# PRU_ICSS_MDIO register map
Vendor: Texas Instruments
Peripheral module from a debugger description file (folder am437x).
Registers are 32-bit, access per field, no defined reset value unless marked. A register's access mark holds for its fields unless they carry their own. Offsets are as the file gives them; lines under a group give offsets from that group; [hi:lo] are bit positions; {n}, {i} and the like mark numbered series; 'fields as' and 'values as' point back to an identical list; <NAME> marks a mode.

## MDIO
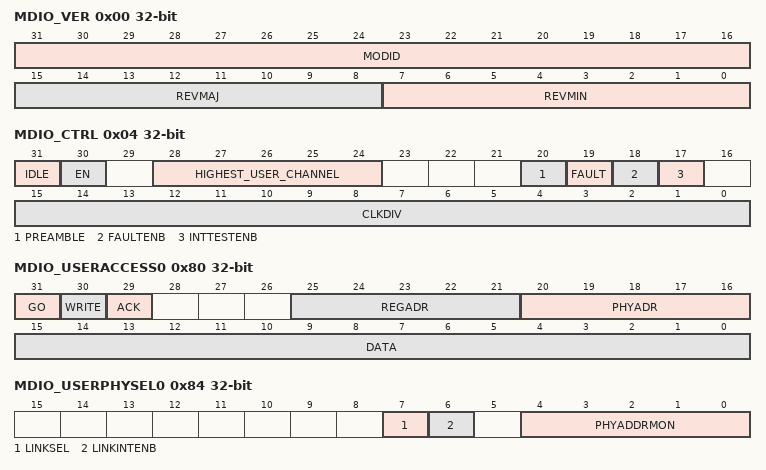
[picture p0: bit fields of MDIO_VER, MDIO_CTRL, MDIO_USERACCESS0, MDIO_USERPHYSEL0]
0x00 MDIO_VER ro
  [31:16] MODID — Identifies type of peripheral.
  [15:8] REVMAJ — Management interface module major revision value.
  [7:0] REVMIN — Management interface module minor revision value.
0x04 MDIO_CTRL
  [31] IDLE ro — MDIO state machine IDLE. [[br]]Set to 1 when the state machine is in the idle state.
    1=en_2_0x1 (State machine is in idle state.); 0=en_1_0x0 (State machine is not in idle state.)
  [30] EN rw — Enable control. [[br]]If the MDIO state machine is active at the time it is disabled, it will complete the current operation before halting and setting the idle bit. [[br]]If using byte access, the enable bit has to be the last bit written in this register.
    1=en_2_0x1 (Enable the MDIO state machine.); 0=en_1_0x0 (Disables the MDIO state machine.)
  [28:24] HIGHEST_USER_CHANNEL ro — Highest user channel. [[br]]This field specifies the highest user access channel that is available in the module and is currently set to 1. [[br]]This implies that the MDIOUSERACCESS1 register is the highest available user access channel.
  [20] PREAMBLE rw — Preamble disable.
    1=en_2_0x1 (Disables this device from sending MDIO frame preambles.); 0=en_1_0x0 (Standard MDIO preamble is used.)
  [19] FAULT rw — Fault indicator. [[br]]This bit is set to 1 if the MDIO pins fail to read back what the device is driving onto them. [[br]]This indicates a physical layer fault and the module state machine is reset. [[br]]Writing a 1 to it clears this bit.
    1=en_2_0x1 (Physical layer fault; the MDIO state machine is reset.); 0=en_1_0x0 (No failure.)
  [18] FAULTENB rw — Fault detect enable. [[br]]This bit has to be set to 1 to enable the physical layer fault detection.
    1=en_2_0x1 (Enables the physical layer fault detection.); 0=en_1_0x0 (Disables the physical layer fault detection.)
  [17] INTTESTENB rw — Interrupt test enable. [[br]]This bit can be set to 1 to enable the host to set the USERINT and LINKINT bits for test purposes.
    1=en_2_0x1 (Enables the host to set the USERINT and LINKINT bits for test purposes.); 0=en_1_0x0 (Interrupt bits are not set.)
  [15:0] CLKDIV rw — Clock divider. [[br]]This field specifies the division ratio between CLK and the frequency of MDIO_CLK. [[br]]MDIO_CLK is disabled when clkdiv is set to 0. [[br]]MDIO_CLK frequency = clk frequency/(clkdiv+1).
0x08 MDIO_ALIVE rw
  [31:0] ALIVE — MDIO alive. [[br]]Each of the 32 bits of this register is set if the most recent access to the PHY with address corresponding to the register bit number was acknowledged by the PHY, the bit is reset if the PHY fails to acknowledge the access. [[br]]Both the user and polling accesses to a PHY will cause the corresponding alive bit to be updated. [[br]]The alive bits are only meant to be used to give an indication of the presence or not of a PHY with the corresponding address. [[br]]Writing a 1 to any bit will clear it, writing a 0 has no effect.
0x0C MDIO_LINK ro
  [31:0] LINK — MDIO link state. [[br]]This register is updated after a read of the Generic Status Register of a PHY. [[br]]The bit is set if the PHY with the corresponding address has link and the PHY acknowledges the read transaction. [[br]]The bit is reset if the PHY indicates it does not have link or fails to acknowledge the read transaction. [[br]]Writes to the register have no effect. [[br]]In addition, the status of the two PHYs specified in the MDIOUSERPHYSEL registers can be determined using the MLINK input pins. [[br]]This is determined by the LINKSEL bit in the MDIOUSERPHYSEL register.
0x10 MDIO_LINKINTRAW
  [1:0] LINKINTRAW rw — MDIO link change event, raw value. [[br]]When asserted 1, a bit indicates that there was an MDIO link change event (that is, change in the MDIOLINK register) corresponding to the PHY address in the MDIOUSERPHYSEL register. [[br]]LINKINTRAW[0] and LINKINTRAW[1] correspond to MDIOUSERPHYSEL0 and MDIOUSERPHYSEL1, respectively. [[br]]Writing a 1 will clear the event and writing 0 has no effect. [[br]]If the INTTESTENB bit in the MDIOCONTROL register is set, the host may set the LINKINTRAW bits to a 1. [[br]]This mode may be used for test purposes.
0x14 MDIO_LINKINTMASKED
  [1:0] LINKINTMASKED rw — MDIO link change interrupt, masked value. [[br]]When asserted 1, a bit indicates that there was an MDIO link change event (that is, change in the MDIO Link register) corresponding to the PHY address in the MDIOUSERPHYSEL register and the corresponding LINKINTENB bit was set. [[br]]LINKINTMASKED[0] and LINKINTMASKED[1] correspond to MDIOUSERPHYSEL0 and MDIOUSERPHYSEL1, respectively. [[br]]Writing a 1 will clear the interrupt and writing 0 has no effect. [[br]]If the INTTESTENB bit in the MDIOCONTROL register is set, the host may set the LINKINT bits to a 1. [[br]]This mode may be used for test purposes.
0x20 MDIO_USERINTRAW
  [1:0] USERINTRAW rw — Raw value of MDIO user command complete event for the MDIOUSERACCESS1 register through the MDIOUSERACCESS0 register, respectively. [[br]]When asserted 1, a bit indicates that the previously scheduled PHY read or write command using that particular MDIOUSERACCESSn register has completed. [[br]]Writing a 1 will clear the event and writing 0 has no effect. [[br]]If the INTTESTENB bit in the MDIOCONTROL register is set, the host may set the USERINTRAW bits to a 1. [[br]]This mode may be used for test purposes.
0x24 MDIO_USERINTMASKED
  [1:0] USERINTMASKED rw — Masked value of MDIO user command complete interrupt for the MDIOUSERACCESS1 register through the MDIOUSERACCESS0 register, respectively. [[br]]When asserted 1, a bit indicates that the previously scheduled PHY read or write command using that particular MDIOUSERACCESSn register has completed and the corresponding USERINTMASKSET bit is set to 1. [[br]]Writing a 1 will clear the interrupt and writing 0 has no effect. [[br]]If the INTTESTENB bit in the MDIOCONTROL register is set, the host may set the USERINTMASKED bits to a 1. [[br]]This mode may be used for test purposes.
0x28 MDIO_USERINTMASKSET
  [1:0] USERINTMASKSET rw — MDIO user interrupt mask set for USERINTMASKED, respectively. [[br]]Writing a bit to 1 will enable MDIO user command complete interrupts for that particular MDIOUSERACCESSn register. [[br]]MDIO user interrupt for a particular MDIOUSERACCESSn register is disabled if the corresponding bit is 0. [[br]]Writing a 0 to this register has no effect.
0x2C MDIO_USERINTMASKCLR
  [1:0] USERINTMASKCLR rw — MDIO user command complete interrupt mask clear for USERINTMASKED, respectively. [[br]]Writing a bit to 1 will disable further user command complete interrupts for that particular MDIOUSERACCESSn register. [[br]]Writing a 0 to this register has no effect.
0x80 MDIO_USERACCESS0
  [31] GO rw — Go. [[br]]Writing a 1 to this bit causes the MDIO state machine to perform an MDIO access when it is convenient for it to do so, this is not an instantaneous process. [[br]]Writing a 0 to this bit has no effect. [[br]]This bit is write able only if the MDIO state machine is enabled. [[br]]This bit will self clear when the requested access has been completed. [[br]]Any writes to the MDIOUSERACCESS0 register are blocked when the GO bit is 1. [[br]]If byte access is being used, the GO bit should be written last.
  [30] WRITE rw — Write enable. [[br]]Setting this bit to a 1 causes the MDIO transaction to be a register write, otherwise it is a register read.
  [29] ACK rw — Acknowledge. [[br]]This bit is set if the PHY acknowledged the read transaction.
  [25:21] REGADR rw — Register address. [[br]]Specifies the PHY register to be accessed for this transaction.
  [20:16] PHYADR rw — PHY address. [[br]]Specifies the PHY to be accesses for this transaction.
  [15:0] DATA rw — User data. [[br]]The data value read from or to be written to the specified PHY register.
0x84 MDIO_USERPHYSEL0
  [7] LINKSEL rw — Link status determination select. [[br]]Set to 1 to determine link status using the MLINK pin. [[br]]Default value is 0 which implies that the link status is determined by the MDIO state machine.
  [6] LINKINTENB rw — Link change interrupt enable. [[br]]Set to 1 to enable link change status interrupts for PHY address specified in PHYADDRMON. [[br]]Link change interrupts are disabled if this bit is set to 0.
    1=en_2_0x1 (Link change status interrupts for PHY address specified in PHYADDRMON bits are enabled.); 0=en_1_0x0 (Link change interrupts are disabled.)
  [4:0] PHYADDRMON rw — PHY address whose link status is to be monitored.
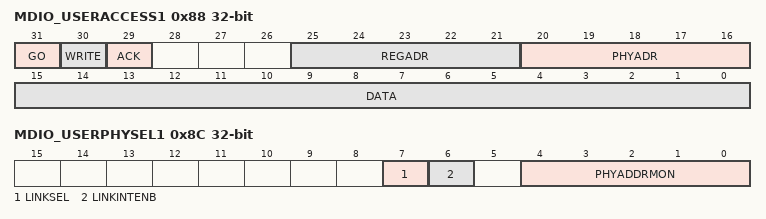
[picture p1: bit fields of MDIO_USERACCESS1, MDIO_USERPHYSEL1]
0x88 MDIO_USERACCESS1
  [31] GO rw — Writing a 1 to this bit causes the MDIO state machine to perform an MDIO access when it is convenient for it to do so, this is not an instantaneous process. [[br]]Writing a 0 to this bit has no effect. [[br]]This bit is write able only if the MDIO state machine is enabled. [[br]]This bit will self clear when the requested access has been completed. [[br]]Any writes to the MDIOUSERACCESS0 register are blocked when the GO bit is 1. [[br]]If byte access is being used, the GO bit should be written last.
  [30] WRITE rw — Write enable. [[br]]Setting this bit to a 1 causes the MDIO transaction to be a register write, otherwise it is a register read.
  [29] ACK rw — Acknowledge. [[br]]This bit is set if the PHY acknowledged the read transaction.
  [25:21] REGADR rw — Register address[[br]] specifies the PHY register to be accessed for this transaction.
  [20:16] PHYADR rw — PHY address[[br]] specifies the PHY to be accesses for this transaction.
  [15:0] DATA rw — User data. [[br]]The data value read from or to be written to the specified PHY register.
0x8C MDIO_USERPHYSEL1
  [7] LINKSEL rw — Link status determination select. [[br]]Set to 1 to determine link status using the MLINK pin. [[br]]Default value is 0 which implies that the link status is determined by the MDIO state machine.
  [6] LINKINTENB rw — Link change interrupt enable. [[br]]Set to 1 to enable link change status interrupts for PHY address specified in PHYADDRMON. [[br]]Link change interrupts are disabled if this bit is cleared to 0.
    1=en_2_0x1 (Link change status interrupts for PHY address specified in PHYADDRMON bits are enabled.); 0=en_1_0x0 (Link change interrupts are disabled)
  [4:0] PHYADDRMON rw — PHY address whose link status is to be monitored.
